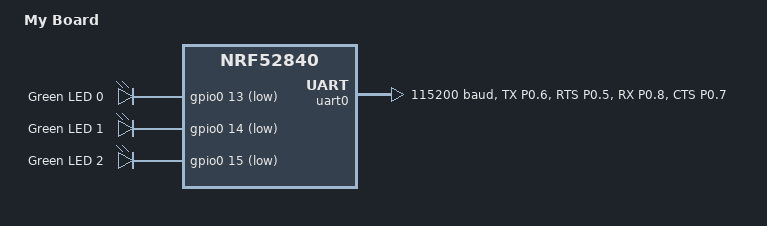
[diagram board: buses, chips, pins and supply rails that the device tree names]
/dts-v1/;
#include <nordic/nrf52840_qiaa.dtsi>
#include <nordic/nrf52840_partition.dtsi>

/ {
	model = "My Board";
	compatible = "iomico,my-board";

	chosen {
		zephyr,console = &uart0;
	};

	aliases {
		led0 = &led0;
		led1 = &led1;
		led2 = &led2;
	};

	leds {
		compatible = "gpio-leds";

		led0: led_0 {
			gpios = <&gpio0 13 GPIO_ACTIVE_LOW>;
			label = "Green LED 0";
		};

		led1: led_1 {
			gpios = <&gpio0 14 GPIO_ACTIVE_LOW>;
			label = "Green LED 1";
		};

		led2: led_2 {
			gpios = <&gpio0 15 GPIO_ACTIVE_LOW>;
			label = "Green LED 2";
		};
	};
};

/* Same UART pins as nRF52840 DK (VCOM on the development kit). */
&pinctrl {
	uart0_default: uart0_default {
		group1 {
			psels = <NRF_PSEL(UART_TX, 0, 6)>,
				 <NRF_PSEL(UART_RTS, 0, 5)>;
		};

		group2 {
			psels = <NRF_PSEL(UART_RX, 0, 8)>,
				 <NRF_PSEL(UART_CTS, 0, 7)>;
			bias-pull-up;
		};
	};

	uart0_sleep: uart0_sleep {
		group1 {
			psels = <NRF_PSEL(UART_TX, 0, 6)>,
				 <NRF_PSEL(UART_RX, 0, 8)>,
				 <NRF_PSEL(UART_RTS, 0, 5)>,
				 <NRF_PSEL(UART_CTS, 0, 7)>;
			low-power-enable;
		};
	};
};

&gpiote {
	status = "okay";
};

&gpio0 {
	status = "okay";
};

&uart0 {
	compatible = "nordic,nrf-uarte";
	status = "okay";
	current-speed = <115200>;
	pinctrl-0 = <&uart0_default>;
	pinctrl-1 = <&uart0_sleep>;
	pinctrl-names = "default", "sleep";
};
